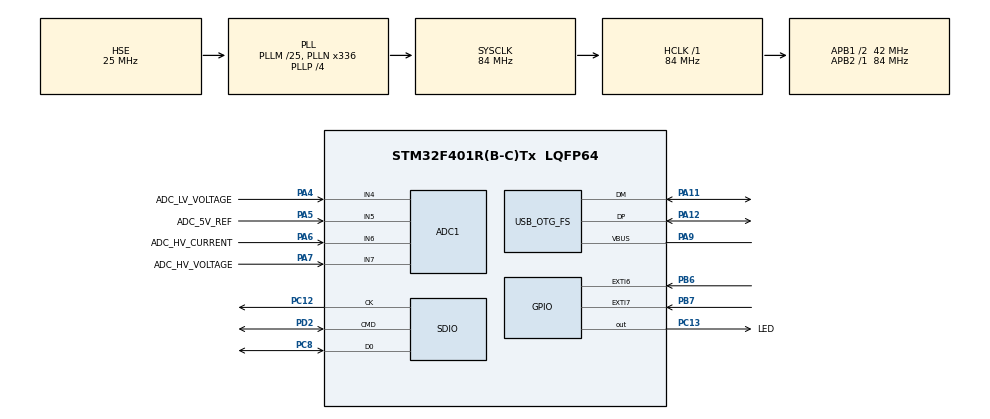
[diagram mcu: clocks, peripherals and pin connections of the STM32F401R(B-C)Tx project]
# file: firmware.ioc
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ADC1.Channel-0\#ChannelRegularConversion=ADC_CHANNEL_4
ADC1.Channel-1\#ChannelRegularConversion=ADC_CHANNEL_5
ADC1.Channel-2\#ChannelRegularConversion=ADC_CHANNEL_6
ADC1.Channel-3\#ChannelRegularConversion=ADC_CHANNEL_7
ADC1.Channel-4\#ChannelRegularConversion=ADC_CHANNEL_TEMPSENSOR
ADC1.Channel-5\#ChannelRegularConversion=ADC_CHANNEL_VREFINT
ADC1.DMAContinuousRequests=ENABLE
ADC1.EOCSelection=ADC_EOC_SEQ_CONV
ADC1.NbrOfConversion=6
ADC1.NbrOfConversionFlag=1
ADC1.Rank-0\#ChannelRegularConversion=1
ADC1.Rank-1\#ChannelRegularConversion=2
ADC1.Rank-2\#ChannelRegularConversion=3
ADC1.Rank-3\#ChannelRegularConversion=4
ADC1.Rank-4\#ChannelRegularConversion=5
ADC1.Rank-5\#ChannelRegularConversion=6
ADC1.SamplingTime-0\#ChannelRegularConversion=ADC_SAMPLETIME_480CYCLES
ADC1.SamplingTime-1\#ChannelRegularConversion=ADC_SAMPLETIME_480CYCLES
ADC1.SamplingTime-2\#ChannelRegularConversion=ADC_SAMPLETIME_480CYCLES
ADC1.SamplingTime-3\#ChannelRegularConversion=ADC_SAMPLETIME_480CYCLES
ADC1.SamplingTime-4\#ChannelRegularConversion=ADC_SAMPLETIME_480CYCLES
ADC1.SamplingTime-5\#ChannelRegularConversion=ADC_SAMPLETIME_480CYCLES
ADC1.ScanConvMode=ENABLE
ADC1.master=1
Dma.ADC1.0.Direction=DMA_PERIPH_TO_MEMORY
Dma.ADC1.0.FIFOMode=DMA_FIFOMODE_DISABLE
Dma.ADC1.0.Instance=DMA2_Stream0
Dma.ADC1.0.MemDataAlignment=DMA_MDATAALIGN_WORD
Dma.ADC1.0.MemInc=DMA_MINC_ENABLE
Dma.ADC1.0.Mode=DMA_CIRCULAR
Dma.ADC1.0.PeriphDataAlignment=DMA_PDATAALIGN_WORD
Dma.ADC1.0.PeriphInc=DMA_PINC_DISABLE
Dma.ADC1.0.Priority=DMA_PRIORITY_LOW
Dma.Request0=ADC1
FATFS._USE_FIND=1
FATFS._USE_LABEL=1
FATFS._USE_LFN=1
Mcu.Family=STM32F4
Mcu.Name=STM32F401R(B-C)Tx
Mcu.Package=LQFP64
NVIC.ADC_IRQn=true\:0\:0\:false\:false\:true\:true\:true\:true
NVIC.DMA2_Stream0_IRQn=true\:0\:0\:false\:false\:true\:false\:true\:true
NVIC.EXTI9_5_IRQn=true\:0\:0\:false\:false\:true\:true\:true\:true
NVIC.OTG_FS_IRQn=true\:0\:0\:false\:false\:true\:true\:true\:true
NVIC.PriorityGroup=NVIC_PRIORITYGROUP_4
NVIC.SDIO_IRQn=true\:0\:0\:false\:false\:true\:true\:true\:true
NVIC.TIM5_IRQn=true\:0\:0\:false\:false\:true\:true\:true\:true
PA11.Mode=Device_Only
PA11.Signal=USB_OTG_FS_DM
PA12.Mode=Device_Only
PA12.Signal=USB_OTG_FS_DP
PA13.Mode=Serial_Wire
PA13.Signal=SYS_JTMS-SWDIO
PA14.Mode=Serial_Wire
PA14.Signal=SYS_JTCK-SWCLK
PA4.GPIO_Label=ADC_LV_VOLTAGE
PA4.Signal=ADCx_IN4
PA5.GPIO_Label=ADC_5V_REF
PA5.Signal=ADCx_IN5
PA6.GPIO_Label=ADC_HV_CURRENT
PA6.Signal=ADCx_IN6
PA7.GPIO_Label=ADC_HV_VOLTAGE
PA7.Signal=ADCx_IN7
PA9.Mode=Activate_VBUS
PA9.Signal=USB_OTG_FS_VBUS
PB6.Signal=GPXTI6
PB7.Signal=GPXTI7
PC12.Mode=SD_1_bit
PC12.Signal=SDIO_CK
PC13-ANTI_TAMP.GPIO_Label=LED
PC13-ANTI_TAMP.Signal=GPIO_Output
PC14-OSC32_IN.Mode=LSE-External-Oscillator
PC14-OSC32_IN.Signal=RCC_OSC32_IN
PC15-OSC32_OUT.Mode=LSE-External-Oscillator
PC15-OSC32_OUT.Signal=RCC_OSC32_OUT
PC8.GPIO_PuPd=GPIO_PULLUP
PC8.Mode=SD_1_bit
PC8.Signal=SDIO_D0
PD2.GPIO_PuPd=GPIO_PULLUP
PD2.Mode=SD_1_bit
PD2.Signal=SDIO_CMD
PH0\ -\ OSC_IN.Mode=HSE-External-Oscillator
PH0\ -\ OSC_IN.Signal=RCC_OSC_IN
PH1\ -\ OSC_OUT.Mode=HSE-External-Oscillator
PH1\ -\ OSC_OUT.Signal=RCC_OSC_OUT
ProjectManager.HeapSize=0x2000
ProjectManager.StackSize=0x1000
ProjectManager.TargetToolchain=Makefile
RCC.48MHZClocksFreq_Value=48000000
RCC.AHBFreq_Value=84000000
RCC.APB1CLKDivider=RCC_HCLK_DIV2
RCC.APB1Freq_Value=42000000
RCC.APB1TimFreq_Value=84000000
RCC.APB2Freq_Value=84000000
RCC.APB2TimFreq_Value=84000000
RCC.CortexFreq_Value=84000000
RCC.HCLKFreq_Value=84000000
RCC.HSE_VALUE=25000000
RCC.HSI_VALUE=16000000
RCC.PLLM=25
RCC.PLLN=336
RCC.PLLP=RCC_PLLP_DIV4
RCC.PLLQ=7
RCC.RCC_RTC_Clock_Source=RCC_RTCCLKSOURCE_LSE
RCC.RCC_RTC_Clock_SourceVirtual=RCC_RTCCLKSOURCE_LSE
RCC.RCC_RTC_Clock_Source_FROM_HSE=RCC_RTCCLKSOURCE_HSE_DIV25
RCC.SYSCLKFreq_VALUE=84000000
RCC.SYSCLKSource=RCC_SYSCLKSOURCE_PLLCLK
RCC.VCOOutputFreq_Value=336000000
RTC.Date=12
RTC.Month=RTC_MONTH_MAY
RTC.WeekDay=RTC_WEEKDAY_FRIDAY
RTC.Year=99
SDIO.ClockDiv=8
SDIO.HardwareFlowControl=SDIO_HARDWARE_FLOW_CONTROL_ENABLE
SH.ADCx_IN4.0=ADC1_IN4,IN4
SH.ADCx_IN5.0=ADC1_IN5,IN5
SH.ADCx_IN6.0=ADC1_IN6,IN6
SH.ADCx_IN7.0=ADC1_IN7,IN7
TIM5.Period=100 - 1
TIM5.Prescaler=8400 - 1
USB_OTG_FS.VirtualMode=Device_Only
VP_ADC1_TempSens_Input.Mode=IN-TempSens
VP_ADC1_Vref_Input.Mode=IN-Vrefint
VP_FATFS_VS_SDIO.Mode=SDIO
VP_RTC_VS_RTC_Activate.Mode=RTC_Enabled
VP_RTC_VS_RTC_Calendar.Mode=RTC_Calendar
VP_TIM5_VS_ClockSourceINT.Mode=Internal
board=custom

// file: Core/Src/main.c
/* USER CODE BEGIN Header */
/**
  ******************************************************************************
  * @file           : main.c
  * @brief          : Main program body
  ******************************************************************************
  * @attention
  *
  * Copyright (c) 2024 STMicroelectronics.
  * All rights reserved.
  *
  * This software is licensed under terms that can be found in the LICENSE file
  * in the root directory of this software component.
  * If no LICENSE file comes with this software, it is provided AS-IS.
  *
  ******************************************************************************
  */
/* USER CODE END Header */
#include "main.h"
#include "adc.h"
#include "dma.h"
#include "fatfs.h"
#include "rtc.h"
#include "sdio.h"
#include "tim.h"
#include "gpio.h"

/* USER CODE BEGIN Includes */
#include <stdio.h>
#include "energymeter.h"
/* USER CODE END Includes */

void SystemClock_Config(void);

int _write(int file, uint8_t *ptr, int len)
{
    (void)file;
    (void)ptr;
    return len;
}
/* USER CODE END 0 */

int main(void)
{

  /* MCU Configuration--------------------------------------------------------*/

  /* Reset of all peripherals, Initializes the Flash interface and the Systick. */
  HAL_Init();

  /* Configure the system clock */
  SystemClock_Config();

  /* Initialize all configured peripherals */
  MX_GPIO_Init();
  MX_DMA_Init();
  MX_ADC1_Init();
  MX_RTC_Init();
  MX_TIM5_Init();
  MX_SDIO_SD_Init();
  MX_FATFS_Init();
  /* USER CODE BEGIN 2 */
  energymeter_init();
  /* USER CODE END 2 */

  /* Infinite loop */
  while (1) {

  }
}

void SystemClock_Config(void)
{
  RCC_OscInitTypeDef RCC_OscInitStruct = {0};
  RCC_ClkInitTypeDef RCC_ClkInitStruct = {0};

  /** Configure the main internal regulator output voltage
  */
  __HAL_RCC_PWR_CLK_ENABLE();
  __HAL_PWR_VOLTAGESCALING_CONFIG(PWR_REGULATOR_VOLTAGE_SCALE2);

  /** Initializes the RCC Oscillators according to the specified parameters
  * in the RCC_OscInitTypeDef structure.
  */
  RCC_OscInitStruct.OscillatorType = RCC_OSCILLATORTYPE_HSE|RCC_OSCILLATORTYPE_LSE;
  RCC_OscInitStruct.HSEState = RCC_HSE_ON;
  RCC_OscInitStruct.LSEState = RCC_LSE_ON;
  RCC_OscInitStruct.PLL.PLLState = RCC_PLL_ON;
  RCC_OscInitStruct.PLL.PLLSource = RCC_PLLSOURCE_HSE;
  RCC_OscInitStruct.PLL.PLLM = 25;
  RCC_OscInitStruct.PLL.PLLN = 336;
  RCC_OscInitStruct.PLL.PLLP = RCC_PLLP_DIV4;
  RCC_OscInitStruct.PLL.PLLQ = 7;
  if (HAL_RCC_OscConfig(&RCC_OscInitStruct) != HAL_OK)
  {
    Error_Handler();
  }

  /** Initializes the CPU, AHB and APB buses clocks
  */
  RCC_ClkInitStruct.ClockType = RCC_CLOCKTYPE_HCLK|RCC_CLOCKTYPE_SYSCLK
                              |RCC_CLOCKTYPE_PCLK1|RCC_CLOCKTYPE_PCLK2;
  RCC_ClkInitStruct.SYSCLKSource = RCC_SYSCLKSOURCE_PLLCLK;
  RCC_ClkInitStruct.AHBCLKDivider = RCC_SYSCLK_DIV1;
  RCC_ClkInitStruct.APB1CLKDivider = RCC_HCLK_DIV2;
  RCC_ClkInitStruct.APB2CLKDivider = RCC_HCLK_DIV1;

  if (HAL_RCC_ClockConfig(&RCC_ClkInitStruct, FLASH_LATENCY_2) != HAL_OK)
  {
    Error_Handler();
  }
}

/* USER CODE BEGIN 4 */
uint32_t error_status; // module error status
/* USER CODE END 4 */

void Error_Handler(void)
{
  /* USER CODE BEGIN Error_Handler_Debug */
  /* User can add his own implementation to report the HAL error return state */
  __disable_irq();

  DEBUG_MSG("!!! ERROR !!!\r\nCODE: %lu\r\n", error_status);

  while (TRUE) {
    HAL_GPIO_TogglePin(LED_GPIO_Port, LED_Pin);
    HAL_Delay(100 * (1 << error_status));
  }

  NVIC_SystemReset(); // reset? or not?
  /* USER CODE END Error_Handler_Debug */
}
